# TC37XPD register map
Vendor: Infineon; Series: ATVMC; File version: 100
CPU: other r0p0, little endian, MPU, FPU, vendor SysTick, 4 interrupt priority bits
Registers are 32-bit, read-write, reset 0x0 unless marked. A register's access mark holds for its fields unless they carry their own. Offsets are from the block's base; [hi:lo] are bit positions; lines under a group give offsets from that group; {n}, {i} and the like mark numbered series.

## SENT
Base 0xF0003000
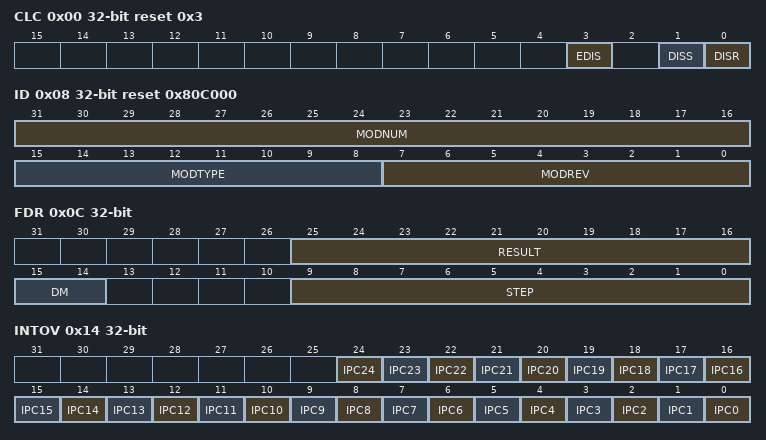
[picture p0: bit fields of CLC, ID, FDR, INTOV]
0x00 CLC access per field reset 0x3 — Clock Control Register resetvalue={Application Reset:0x3}
  [3] EDIS rw — Sleep Mode Enable Control EDIS. Used to control module 8217 s sleep mode.
  [1] DISS ro — Module Disable Status Bit DISS. Bit indicates the current status of the module.
  [0] DISR rw — Module Disable Request Bit DISR. Used for enable disable control of the module.
0x08 ID ro reset 0x80C000 (reset mask 0xFFFFFF00) — Module Identification Register resetvalue={Application Reset:0x080C000}
  [31:16] MODNUM — Module Number Value MODNUM. This bit field defines the module identification number for the SENT 0080 H
  [15:8] MODTYPE — Module Type MODTYPE. This bit field defines the module as a 32 bit module C0 H
  [7:0] MODREV — Module Revision Number MODREV. This bit field defines the module revision number. The value of a module revision starts with 01 H first revision .
0x0C FDR access per field — SENT Fractional Divider Register resetvalue={Application Reset:0x0}
  [25:16] RESULT ro — Result Value RESULT. Bit field for the addition result.
  [15:14] DM rw — Divider Mode DM. DM selects normal or fractional divider mode.
  [9:0] STEP rw — Step Value STEP. Reload or addition value for RESULT.
0x14 INTOV ro — Interrupt Overview Register resetvalue={Application Reset:0x0}
  [n] IPC{n} (n=0..24) — Interrupt Pending on Channel 24 IPC24. If any interrupt requested flag is set for channel y in register INTSTATy AND the referring interrupt is enabled in INTENx then IPCy is set. It is automatically reset if all flags in INTSTATy are cleared for which the referring interrupt is enabled in INTENx. Not all IPC0 24 are available on all products the number of Interrupt Pending on Channel is equivalent to the SENT channels available e.g 4 SENT channels has 4 Interrupt Pending IPC0 3 and vice versa.
0x18 TSR ro — Module Time Stamp Register resetvalue={Application Reset:0x0}
  [31:0] CTS — Current Time Stamp for the Module CTS. This bit field shows the current time stamp.
0x1C TPD — Time Stamp Predivider Register resetvalue={Application Reset:0x0}
  [19:0] TDIV — Divider Factor of Pre Divider for TSR TDIV. Divides f fracdiv by TDIV 1 and drives TSR.
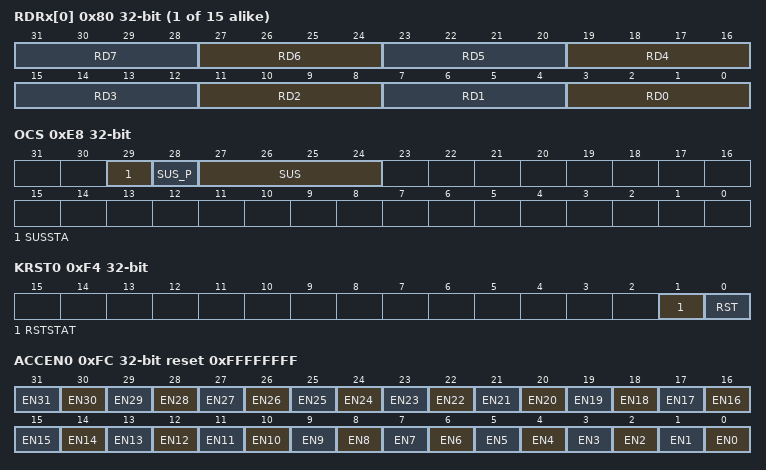
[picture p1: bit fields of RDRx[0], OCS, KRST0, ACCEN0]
{0x80+4i} RDRx[{i}] (i=0..14) ro — Receive Data Register 0 resetvalue={Application Reset:0x0}
  [4n+3:4n] RD{n} (n=0..7) — Receive Data Nibble 7 RD7. RDy shows the nibble from the received frame that is sorted to this position. It can be selected by any of VIEWx.RDNPy y 160 160 0 7 . By default all nibbles are sorted to RD0 as the reset value of VIEW is 0x0000 160 0000H. I.e. at the end of frame reception RD0 contains the last data nibble of the frame.
0xE8 OCS access per field — OCDS Control and Status resetvalue={Debug Reset:0x0}
  [29] SUSSTA ro — Suspend State SUSSTA
  [28] SUS_P wo — SUS Write Protection SUS P. SUS is only written when SUS P is 1 otherwise unchanged. Read as 0.
  [27:24] SUS rw — OCDS Suspend Control SUS. Controls the sensitivity to the suspend signal coming from the OCDS Trigger Switch OTGS
0xEC KRSTCLR wo — Kernel Reset Status Clear Register resetvalue={Application Reset:0x0}
  [0] CLR — Kernel Reset Status Clear CLR. Read always as 0.
0xF0 KRST1 — Kernel Reset Register 1 resetvalue={Application Reset:0x0}
  [0] RST — Kernel Reset RST. This reset bit can be used to request for a kernel reset. The kernel reset will be executed if the reset bits of both kernel reset registers is set. The RST bit will be cleared re set to 0 by the BPI FPI after the kernel reset was executed.
0xF4 KRST0 access per field — Kernel Reset Register 0 resetvalue={Application Reset:0x0}
  [1] RSTSTAT ro — Kernel Reset Status RSTSTAT. This bit indicates wether a kernel reset was executed or not. This bit is set by the BPI FPI after the execution of a kernel reset in the same clock cycle both reset bits. This bit can be cleared by writing with 1 to the CLR bit in the related KRSTCLR register.
  [0] RST rw — Kernel Reset RST. This reset bit can be used to request for a kernel reset. The kernel reset will be executed if the reset bits of both kernel registers are set. The RST bit will be cleared re set to 0 by the BPI FPI after the kernel reset was executed.
0xFC ACCEN0 reset 0xFFFFFFFF — Access Enable Register 0 resetvalue={Application Reset:0x0FFFFFFFF}
  [n] EN{n} (n=0..31) — Access Enable for Master TAG ID 31 EN31. This bit enables write access to the module kernel addresses for transactions with the Master TAG ID n
{0x100+0x40*i} CH[{i}] (i=0..14) group
  0x00 CPDRx — Channel Pre Divider Register 0 resetvalue={Application Reset:0x0}
    [11:0] PDIV — Divider Factor of Pre Divider for Channel x PDIV. Divides f fracdiv by PDIV 1 and delivers f pdiv x to the Channel Fractional Divider. RCR.CEN must be cleared before changing CPDR.PDIV or CFDR.DIV.
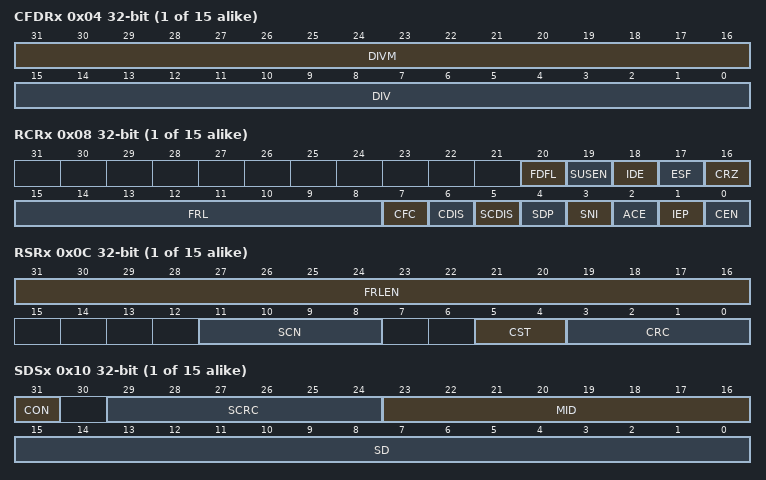
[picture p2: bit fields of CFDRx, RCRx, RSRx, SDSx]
  0x04 CFDRx access per field — Channel Fractional Divider Register 0 resetvalue={Application Reset:0x0}
    [31:16] DIVM ro — Measured Divider Value DIVM. DIVM is automatically updated by HW to adjust the receiver frequency to the current sender frequency. This value is kept automatically in the range of 75 DIV lt DIVM lt 125 DIV Write data is ignored.
    [15:0] DIV rw — Divider Value DIV. Initial and reference divider value for the CFDR. DIV must be programmed gt 0. If cleared DIV becomes 1. If written DIVM is updated automatically with the same value. This can be helpful to accelerate a return to normal. RCR.CEN must be cleared before changing CPDR.PDIV or CFDR.DIV. DIV must be set in the range of 2200 49100 .
  0x08 RCRx — Receiver Control Register 0 resetvalue={Application Reset:0x0}
    [20] FDFL — Frequency Drift Check based on Frame Length FDFL. This bit is used for frames with pause pulse only. If set the drift error is not checked by HW. Instead counter values DIVM and FRLEN are provided to the SW for checking the frequency drift. IEP Pause Pulse expected and IDE no HW check of drift error must always be set 1 together with FDFL. Note If FDFL is set RCR.CFC is ignored and the checks described there are not executed.
    [19] SUSEN — Suspend Enable SUSEN. This bit makes it possible to set the SENT channel into Suspend Mode via OCDS on chip debug support Bit SUSEN is reset via OCDS Reset.
    [18] IDE — Ignore Drift Error Mode IDE. This bit selects if drift errors lead to frame rejection and if an interrupt INTSTAT.FDI is generated. Used if sensors are triggered by SPC. During a long pause period the accumulated drift could be more than 1.5625 . In this special case setting IDE is useful.
    [17] ESF — Enhanced Serial Frame Mode ESF. This bit selects the serial frame structure.
    [16] CRZ — CRC with Zero Nibble for Serial Data CRZ. This bit selects the CRC method. If CRZ is cleared augmentation is selected i.e a ZERO NIBBLE is added at the end of CRC calculation only in calculation . E.g. as 7th nibble in case of 6 data nibbles The enhanced serial message 18 Frames 6 bit CRC is not controlled by CRZ but the 6 bit CRC is always augmented according to standard.
    [15:8] FRL — Frame Length FRL. FRL determines the number of data nibbles per frame that the SENT channel x is setup for. Note that FRL does not include the Synchronization Calibration Pulse the Status and Communication nibble the CRC nibble nor the additional zero length nibble that might be introduced by use of SPC If more than 8 nibbles are configured please note In addition to the receive success interrupt RSI at the successfully received end of a frame a receive data interrupt RDI is issued each time 8 nibbles have been transferred to the Receive Data Register RDRx. At the end of a frame RDI is issued if RSI is issued. If an error occurred RDI is not set at the end of a frame. If no CRC has been received at the point in time where RDI is issued the receive data interrupt is no indication whether or not the transfer was successful so far. A CRC Error Interrupt is issued at the end of the frame if Automatic CRC check is enabled and the CRC is wrong.
    [7] CFC — Consecutive Frame Check CFC. This bit determines the way the most recently received frame buffer is indicated as valid. Note If FDFL is set CFC is ignored and the checks described here are not executed.
    [6] CDIS — CRC Disabled Mode CDIS. This bit selects the CRC disabled mode.
    [5] SCDIS — CRC for Serial Data Disabled Mode SCDIS. This bit selects the CRC disabled mode.
    [4] SDP — Serial Data Processing Mode SDP. This bit switches automatic serial data processing on.
    [3] SNI — Status Nibble Included in CRC SNI. When SNI is set the status Nibble is included in signal data CRC.
    [2] ACE — Alternative CRC Mode Enable ACE. When ACE is set the CRC is calculated in an alternative way for both fast signal and slow serial message data path. If ESF is set the standard 6 bit CRC is always used for the serial message and ACE is ignored.
    [1] IEP — Ignore End Pulse IEP. When IEP is set an end pulse is ignored. An end pulse can be generated in SPC mode or as pause pulse. For systems with an end pulse during synchronize or re synchronize of reception if calibration pulses are detected one immediately following the other the first calibration pulse shall be ignored as it may be a pause pulse with duration matching the calibration pulse range.
    [0] CEN — Channel Enable CEN. When CEN is set the receiver of channel x is enabled. The internal receiver state machine can be initialized by switching the channel off and on. This does not change the current register content.
  0x0C RSRx ro — Receive Status Register 0 resetvalue={Application Reset:0x0}
    [31:16] FRLEN — Frame Length including Pause Nibble FRLEN. of last frame. Bit FRLEN0 is on bit position 16. FRLEN is a 16 bit counter with saturation stops at 0xFFFF 65.535 and is driven by f pdiv . This counter supports monitoring the following condition for messages with pause pulse and fixed message length Ratio of calibration pulse to message length varies by gt 1 64 or lt 1 64 from one message to another. FRLEN is valid after RSI. See chapter 8220 Support for Frequency Drift Analysis in Frames with Pause Pulse 8221 . FRLEN must not be clocked if IEP or IDE or FDFL is cleared.
    [11:8] SCN — Status and Communication Nibble SCN. of last frame. SCN0 is on bit position 8.
    [5:4] CST — Channel Status CST. CST shows the current status of channel x.
    [3:0] CRC — CRC CRC. of last frame. CRC0 is on bit position 0.
  0x10 SDSx ro — Serial Data and Status Register 0 resetvalue={Application Reset:0x0}
    [31] CON — Configuration bit CON. of last serial frame.
    [29:24] SCRC — SCRC SCRC. CRC of last serial data frame. CRC0 is on position 24. If RCR.ESF is cleared bits 29 28 are always zero.
    [23:16] MID — Message ID MID. of last serial data frame. ID0 is on bit position 16. If RCR.ESF is cleared or if SDS.CON is set bits 23 20 are zero.
    [15:0] SD — Serial Data SD. of last serial data frame. SD0 is on bit position 0. Usually all 16 data bits are used. If RCR.ESF is cleared 8 bits of data are available and bits 15 8 are zero. If RCR.ESF is set and if SDS.CON is cleared 12 bits of data are available and bits 15 12 are zero.
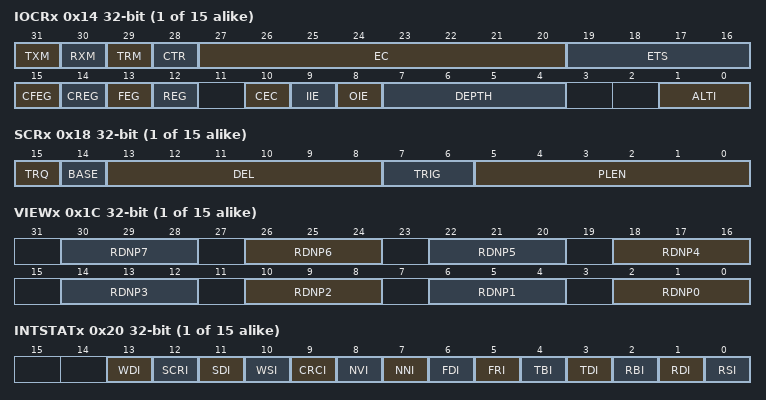
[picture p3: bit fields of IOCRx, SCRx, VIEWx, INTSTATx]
  0x14 IOCRx access per field (reset mask 0xFFFFFFF) — Input and Output Control Register 0 resetvalue={Application Reset:0x0}
    [31] TXM ro — Transmit Monitor for Channel x TXM. Shows the status of the transmit signal of channel x inverted as specified by OIE. Reset value of TXM is X.
    [30] RXM ro — Receive Monitor for Channel x RXM. Shows the status of the receive signal of channel x after glitch filtering and inverted as specified by IIE. Reset value of RXM is X.
    [29] TRM ro — Trigger Monitor Flag for Channel x TRM. Shows the status of the trigger detection of channel x TRM is cleared by setting CTR. Reset value of TRM is 0.
    [28] CTR rw — Clear Trigger Monitor Flag for Channel x CTR. Clears the status flag TRM CTR always read zero. Reset value of CTR is 0.
    [27:20] EC ro — Edge Counter EC. This bit field contains a counter with saturation stops at 0xFF . It is incremented with any falling edge that appears on the input pin selected by IOCR.ALTI. Note that this holds true in all states STOP INITIALIZED RUNNING SYNCHRONIZED . It is intended for debugging in particular to find a bubbling idiot that sends before enabling the module.
    [19:16] ETS rw — External Trigger Select ETS. Selects the external trigger line if SCRx.TRIG is programmed to 11B. In some products not all inputs are connected. See CROSSREFERENCE .
    [15] CFEG rw — Clear Falling Edge Glitch Flag for Channel x CFEG. Clears the status flag FEG CFEG always read zero.
    [14] CREG rw — Clear Rising Edge Glitch Flag for Channel x CREG. Clears the status flag REG CREG always read zero.
    [13] FEG ro — Falling Edge Glitch Flag for Channel x FEG. Shows the status of the glitch detection of channel x FEG is cleared by setting CFEG.
    [12] REG ro — Rising Edge Glitch Flag for Channel x REG. Shows the status of the glitch detection of channel x REG is cleared by setting CREG.
    [10] CEC wo — Clear Edge Counter CEC. If this bit is set IOCR.EC is cleared. Always reads back as 0 .
    [9] IIE rw — Input Inverter Enable Channel x IIE. Selects the Pulse Polarity of the input of channel x
    [8] OIE rw — Output Inverter Enable Channel x OIE. Selects the Pulse Polarity of the output of channel x
    [7:4] DEPTH rw — Digital Glitch Filter Depth DEPTH. DEPTH determines the number of port input samples clocked with f pdiv that are taken into account for the calculation of the floating average. The higher DEPTH is chosen to be the longer the glitches that are suppressed and the longer the delay of the input signal introduced by this filter.
    [1:0] ALTI rw — Alternate Input Select ALTI. Selects the alternate input for channel y
  0x18 SCRx access per field — SPC Control Register 0 resetvalue={Application Reset:0x0}
    [15] TRQ ro — Transfer Request in Progress TRQ. While an SPC Pulse is being sent this bit is set. Write access is ignored.
    [14] BASE rw — Time Base BASE. Selects the Pulse Time Base
    [13:8] DEL rw — Delay Length DEL. Selects how long the SPC pulse is delayed after the trigger condition. The time base is the measured tick time of the latest received frame if selected so by BASE. In case this measured tick time was invalid or not already available after enable of the channel the nominal time base of the module is used.
    [7:6] TRIG rw — Trigger Source and Mode Selection TRIG. Selects the Trigger Source and Mode. The internal sender state machine can be initialized by switching the channel off TRIG is cleared and on. This does not change the current register content.
    [5:0] PLEN rw — Pulse Length PLEN. Defines the length of the pulse in tick times. The time base is the measured tick time of the latest received frame if selected so by BASE. In case this measured tick time was invalid or not already available after enable of the channel the nominal time base of the module is used.
  0x1C VIEWx — Receive Data View Register 0 resetvalue={Application Reset:0x0}
    [4n+2:4n] RDNP{n} (n=0..7) — Receive Data Target Nibble Pointer 7 RDNP7. RDNPy points to the Nibble in Receive Data Register RDRx where the nibble y from the received frame is sorted to. Nibble 0 is the first data nibble in the frame. It gets moved to the position defined in RDNP0. And on. RDNPy must be written before first frame reception. All RDNPy must have different values. Higher RDNPy overwrite lower RDNPy.
  0x20 INTSTATx ro — Interrupt Status Register 0 resetvalue={Application Reset:0x0}
    [13] WDI — Watch Dog Error Request Flag WDI. This bit is set if the Watch Dog Timer of the channel x expires. This bit can be cleared by bit INTCLRx.WDI. This bit can be set by bit INTSETx.WDI. This bit is set independently from INTENx.
    [12] SCRI — Serial Data CRC Error Request Flag SCRI. This bit is set if the CRC of the serial message fails. In Enhanced Serial Message Format this includes a check of the Serial Communication Nibble for correct 0 values of bit 3 in frames 7 13 and 18. This bit can be cleared by bit INTCLRx.SCRI. This bit can be set by bit INTSETx.SCRI. This bit is set independently from INTENx.
    [11] SDI — Serial Data Receive Interrupt Request Flag SDI. This bit is set after all serial data bits have been received via the Status and Communication nibble. Depending on bit RCRx.SCDIS this indicates a successful check of the CRC. This bit can be cleared by bit INTCLRx.SDI. This bit can be set by bit INTSETx.SDI. This bit is set independently from INTENx.
    [10] WSI — Wrong Status and Communication Nibble Error Request Flag WSI. In Short Serial Frame Mode RCR.ESF is cleared this bit is set if the Status and Communication nibble shows a start bit in a frame other than frame number n x 16. In Enhanced Serial Frame Mode this bit is without function. This bit can be cleared by bit INTCLRx.WSI. This bit can be set by bit INTSETx.WSI. This bit is set independently from INTENx.
    [9] CRCI — CRC Error Request Flag CRCI. This bit is set if the CRC fails. This bit can be cleared by bit INTCLRx.CRCI. This bit can be set by bit INTSETx.CRCI. This bit is set independently from INTENx.
    [8] NVI — Nibbles Value out of Range Request Flag NVI. This bit is set after a too long or too short nibble pulse has been received. I.e. value lt 0 or value gt 15. This bit can be cleared by bit INTCLRx.NVI. This bit can be set by bit INTSETx.NVI. This bit is set independently from INTENx.
    [7] NNI — Number of Nibbles Wrong Request Flag NNI. This bit is set after more nibbles have been received than expected or a Synchronization Calibration Pulse is received too early thus too few nibbles have been received. This bit can be cleared by bit INTCLRx.NNI. This bit can be set by bit INTSETx.NNI. This bit is set independently from INTENx.
    [6] FDI — Frequency Drift Interrupt Request Flag FDI. This bit is set after a subsequent Synchronization Calibration pulse was received that deviates more than 1.5625 1 64 from its predecessor. See RCR.CFC This bit can be cleared by bit INTCLRx.FDI. This bit can be set by bit INTSETx.FDI. This bit is set independently from INTENx.
    [5] FRI — Frequency Range Interrupt Request Flag FRI. This bit is set after a Synchronization Calibration pulse was received that deviates more than 25 from the nominal value. The referring data is ignored. This bit can be cleared by bit INTCLRx.FRI. This bit can be set by bit INTSETx.FRI. This bit is set independently from INTENx.
    [4] TBI — Transmit Buffer Underflow Interrupt Request Flag TBI. This bit is set after data has been completely transferred PLEN exceeded and no new data was written to SCRx. This bit is NOT cleared by writing SCRx. This bit can be cleared by bit INTCLRx.TBI. This bit can be set by bit INTSETx.TBI. This bit is set independently from INTENx.
    [3] TDI — Transfer Data Interrupt Request Flag TDI. This bit is set after the trigger condition was detected. Data to be transferred has been moved internally. Thus a new value can be written to SCRx. This can be used for back to back transfers. This bit is automatically cleared by writing SCRx. This bit can be cleared by bit INTCLRx.TDI. This bit can be set by bit INTSETx.TDI. This bit is set independently from INTENx.
    [2] RBI — Receive Buffer Overflow Interrupt Request Flag RBI. This bit is set after a frame has been received while the old one was not read from RDRx. I.e. the kernel wants to set any of the two interrupts RSI and RDI and finds any of these two interrupts already set.The old data is overwritten by the new data. This bit is NOT cleared by reading RDRx. This bit can be cleared by bit INTCLRx.RBI. This bit can be set by bit INTSETx.RBI. This bit is set independently from INTENx.
    [1] RDI — Receive Data Interrupt Request Flag RDI. RDI is activated when a received frame is moved to a Receive Data Register RDR. Both RDI and RSI will be issued together in normal use cases where the frame size is not bigger than 8 nibbles and CRC is correct or not checked if RCRx.CDIS is cleared . For frames with more than 8 nibbles RDI is issued after 8 nibbles. After the last nibbles of the frame are received a last RDI and an RSI are issued together. Note that this is true independently from RCR.FDFL. This bit can be cleared by bit INTCLRx.RDI. This bit can be set by bit INTSETx.RDI. This bit is set independently from INTENx.
    [0] RSI — Receive Success Interrupt Request Flag RSI. This bit is set at the successfully received end of a frame. Depending on bit RCRx.CDIS this indicates a successful check of the CRC. This bit can be cleared by bit INTCLRx.RSI. This bit can be set by bit INTSETx.RSI. This bit is set independently from INTENx.
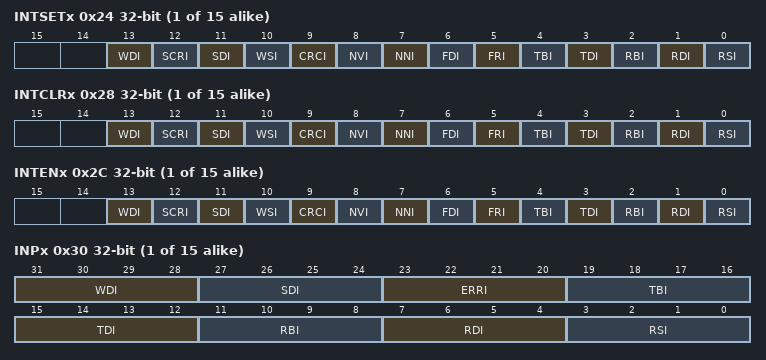
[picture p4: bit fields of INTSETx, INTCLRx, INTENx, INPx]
  0x24 INTSETx wo — Interrupt Set Register 0 resetvalue={Application Reset:0x0}
    [13] WDI — Set Interrupt Request Flag WDI WDI. Setting this bit set bit INTSTATx.WDI. Clearing this bit has no effect. Reading this bit returns always zero.
    [12] SCRI — Set Interrupt Request Flag SCRI SCRI. Setting this bit set bit INTSTATx.SCRI. Clearing this bit has no effect. Reading this bit returns always zero.
    [11] SDI — Set Interrupt Request Flag SDI SDI. Setting this bit set bit INTSTATx.SDI. Clearing this bit has no effect. Reading this bit returns always zero.
    [10] WSI — Set Interrupt Request Flag WSI WSI. Setting this bit set bit INTSTATx.WSI. Clearing this bit has no effect. Reading this bit returns always zero.
    [9] CRCI — Set Interrupt Request Flag CRCI CRCI. Setting this bit set bit INTSTATx.CRCI. Clearing this bit has no effect. Reading this bit returns always zero.
    [8] NVI — Set Interrupt Request Flag NVI NVI. Setting this bit set bit INTSTATx.NVI. Clearing this bit has no effect. Reading this bit returns always zero.
    [7] NNI — Set Interrupt Request Flag NNI NNI. Setting this bit set bit INTSTATx.NNI. Clearing this bit has no effect. Reading this bit returns always zero.
    [6] FDI — Set Interrupt Request Flag FDI FDI. Setting this bit set bit INTSTATx.FDI. Clearing this bit has no effect. Reading this bit returns always zero.
    [5] FRI — Set Interrupt Request Flag FRI FRI. Setting this bit set bit INTSTATx.FRI. Clearing this bit has no effect. Reading this bit returns always zero.
    [4] TBI — Set Interrupt Request Flag TBI TBI. Setting this bit set bit INTSTATx.TBI. Clearing this bit has no effect. Reading this bit returns always zero.
    [3] TDI — Set Interrupt Request Flag TDI TDI. Setting this bit set bit INTSTATx.TDI. Clearing this bit has no effect. Reading this bit returns always zero.
    [2] RBI — Set Interrupt Request Flag RBI RBI. Setting this bit set bit INTSTATx.RBI. Clearing this bit has no effect. Reading this bit returns always zero.
    [1] RDI — Set Interrupt Request Flag RDI RDI. Setting this bit set bit INTSTATx.RDI. Clearing this bit has no effect. Reading this bit returns always zero.
    [0] RSI — Set Interrupt Request Flag RSI RSI. Setting this bit set bit INTSTATx.RSI. Clearing this bit has no effect. Reading this bit returns always zero.
  0x28 INTCLRx wo — Interrupt Clear Register 0 resetvalue={Application Reset:0x0}
    [13] WDI — Clear Interrupt Request Flag WDI WDI. Setting this bit clears bit INTSTATx.WDI. Clearing this bit has no effect. Reading this bit returns always zero.
    [12] SCRI — Clear Interrupt Request Flag SCRI SCRI. Setting this bit clears bit INTSTATx.SCRI. Clearing this bit has no effect. Reading this bit returns always zero.
    [11] SDI — Clear Interrupt Request Flag SDI SDI. Setting this bit clears bit INTSTATx.SDI. Clearing this bit has no effect. Reading this bit returns always zero.
    [10] WSI — Clear Interrupt Request Flag WSI WSI. Setting this bit clears bit INTSTATx.WSI. Clearing this bit has no effect. Reading this bit returns always zero.
    [9] CRCI — Clear Interrupt Request Flag CRCI CRCI. Setting this bit clears bit INTSTATx.CRCI. Clearing this bit has no effect. Reading this bit returns always zero.
    [8] NVI — Clear Interrupt Request Flag NVI NVI. Setting this bit clears bit INTSTATx.NVI. Clearing this bit has no effect. Reading this bit returns always zero.
    [7] NNI — Clear Interrupt Request Flag NNI NNI. Setting this bit clears bit INTSTATx.NNI. Clearing this bit has no effect. Reading this bit returns always zero.
    [6] FDI — Clear Interrupt Request Flag FDI FDI. Setting this bit clears bit INTSTATx.FDI. Clearing this bit has no effect. Reading this bit returns always zero.
    [5] FRI — Clear Interrupt Request Flag FRI FRI. Setting this bit clears bit INTSTATx.FRI. Clearing this bit has no effect. Reading this bit returns always zero.
    [4] TBI — Clear Interrupt Request Flag TBI TBI. Setting this bit clears bit INTSTATx.TBI. Clearing this bit has no effect. Reading this bit returns always zero.
    [3] TDI — Clear Interrupt Request Flag TDI TDI. Setting this bit clears bit INTSTATx.TDI. Clearing this bit has no effect. Reading this bit returns always zero.
    [2] RBI — Clear Interrupt Request Flag RBI RBI. Setting this bit clears bit INTSTATx.RBI. Clearing this bit has no effect. Reading this bit returns always zero.
    [1] RDI — Clear Interrupt Request Flag RDI RDI. Setting this bit clears bit INTSTATx.RDI. Clearing this bit has no effect. Reading this bit returns always zero.
    [0] RSI — Clear Interrupt Request Flag RSI RSI. Setting this bit clears bit INTSTATx.RSI. Clearing this bit has no effect. Reading this bit returns always zero.
  0x2C INTENx — Interrupt Enable Register 0 resetvalue={Application Reset:0x0}
    [13] WDI — Enable Interrupt Request WDI WDI
    [12] SCRI — Enable Interrupt Request SCRI SCRI
    [11] SDI — Enable Interrupt Request SDI SDI
    [10] WSI — Enable Interrupt Request WSI WSI
    [9] CRCI — Enable Interrupt Request CRCI CRCI
    [8] NVI — Enable Interrupt Request NVI NVI
    [7] NNI — Enable Interrupt Request NNI NNI
    [6] FDI — Enable Interrupt Request FDI FDI
    [5] FRI — Enable Interrupt Request FRI FRI
    [4] TBI — Enable Interrupt Request TBI TBI
    [3] TDI — Enable Interrupt Request TDI TDI
    [2] RBI — Enable Interrupt Request RBI RBI
    [1] RDI — Enable Interrupt Request RDI RDI
    [0] RSI — Enable Interrupt Request RSI RSI
  0x30 INPx — Interrupt Node Pointer Register 0 resetvalue={Application Reset:0x0}
    [31:28] WDI — Interrupt Node Pointer for Interrupt WDI WDI. This bit field defines the interrupt node that is requested due to the set condition for bit INTSTATx.WDI if enabled by bit INTENx.WDI . For bit field definition see RSI.
    [27:24] SDI — Interrupt Node Pointer for Interrupt SDI SDI. This bit field defines the interrupt node that is requested due to the set condition for bit INTSTATx.SDI if enabled by bit INTENx.SDI . For bit field definition see RSI.
    [23:20] ERRI — Interrupt Node Pointer for Interrupt FRI FDI NNI NVI CRCI WSI SCRI ERRI. This bit field defines the interrupt node that is requested due to the set condition for bit INTSTATx.FRI if enabled by bit INTENx.FRI or INTSTATx.FDI if enabled by bit INTENx.FDI or INTSTATx.NNI if enabled by bit INTENx.NNI or INTSTATx.NVI if enabled by bit INTENx.NVI or INTSTATx.CRCI if enabled by bit INTENx.CRCI or INTSTATx.WSI if enabled by bit INTENx.WSI or INTSTATx.SCRI if enabled by bit INTENx.SCRI For bit field definition see RSI.
    [19:16] TBI — Interrupt Node Pointer for Interrupt TBI TBI. This bit field defines the interrupt node that is requested due to the set condition for bit INTSTATx.TBI if enabled by bit INTENx.TBI . For bit field definition see RSI.
    [15:12] TDI — Interrupt Node Pointer for Interrupt TDI TDI. This bit field defines the interrupt node that is requested due to the set condition for bit INTSTATx.TDI if enabled by bit INTENx.TDI . For bit field definition see RSI.
    [11:8] RBI — Interrupt Node Pointer for Interrupt RBI RBI. This bit field defines the interrupt node that is requested due to the set condition for bit INTSTATx.RBI if enabled by bit INTENx.RBI . For bit field definition see RSI.
    [7:4] RDI — Interrupt Node Pointer for Interrupt RDI RDI. This bit field defines the interrupt node that is requested due to the set condition for bit INTSTATx.RDI if enabled by bit INTENx.RDI . For bit field definition see RSI.
    [3:0] RSI — Interrupt Node Pointer for Interrupt RSI RSI. This bit field defines the interrupt node that is requested due to the set condition for bit INTSTATx.RSI if enabled by bit INTENx.RSI .
  0x34 WDTx — Watch Dog Timer Register 0 resetvalue={Application Reset:0x0}
    [15:0] WDL — Watch Dog Timer Limit WDL. for channel x .
{0xA80+4i} RTSx[{i}] (i=0..14) ro — Receive Time Stamp Register 0 resetvalue={Application Reset:0x0}
  [31:0] LTS — Last Receive Time Stamp for Channel x LTS. This bit field shows the time stamp of the last frame on channel x.
